# CC1314R10 register map
File version: 1.0
CPU: CM33 1.0, other endian, MPU, FPU, 3 interrupt priority bits
Registers are 32-bit, read-write, reset 0x0 unless marked. A register's access mark holds for its fields unless they carry their own. Offsets are from the block's base; [hi:lo] are bit positions; {n}, {i} and the like mark numbered series; 'fields as' and 'values as' point back to an identical list.

## CRYPTO (part 2 of 2) — DMA Crypto Core is a low power low gate count crypto core with DMA capability and local key storage.
Base 0x58024000
0x5DC AESBLKCNT1 — This counter keeps track of the number of data blocks during AES-CCM and AES-GCM operations. Reading and writing this counter allows interruption and resuming of long CCM or GCM operations. Note that internally, the block counter is used for AAD data as well as encryption/decryption data
  [24:0] AES_BLK_CNT_56_32 — [24:0] [56:32] of Internal block counter for AES GCM and CCM operations. These bits read the block count value that represents the number of blocks to go. This value is valid with saved_context_ready after a request for an intermediate GCM/CCM digest. Writing these registers will restore the internal block counter to the programmed value. This only needs to be done to prepare the engine to continue processing of an interrupted GCM or CCM operation. Also refer to the get_digest and gcm_ccm_continue bits in AES_CTRL register.
{0x600+4i} HASHDATAIN{i} (i=0..2) — HASH Data Input {i} The data input registers should be used to provide input data to the hash module through the slave interface.
  [31:0] HASH_DATA_IN wo — [31:0] HASH_DATA_IN[{32i+31}:{32i}] These registers must be written with the 512-bit or 1024-bit (depending on block size of chosen SHA-2 algorithm) input data. The data lines are connected directly to the data input of the hash module and hence into the engine's internal data buffer. Writing to each of the registers triggers a corresponding 32-bit write enable to the internal buffer. Note: The host may only write the input data buffer when HASHIOBUFCTRL.RFD_IN is 1. If the HASHIOBUFCTRL.RFD_IN is 0, the engine is busy with processing. During processing, it is not allowed to write new input data. For message lengths larger than a block size, multiple blocks of data are written to this input buffer using a handshake through flags of the HASHIOBUFCTRL register. All blocks except the last are required to be 512 bits (or 1024 bits depending on block size) in size. If the last block is not 512 bits ( or 1024 bits depending on block size) long, only the least significant bits of data must be written, but they must be padded with 0s to the next 32-bit boundary. Host read operations from these register addresses return 0s.
0x60C HASHDATAIN3 — HASH Data Input 3 The data input registers should be used to provide input data to the hash module through the slave interface.
  [31:0] HASH_DATA_IN wo — [31:0] HASH_DATA_IN[127:96] These registers must be written with the 512-bit or 1024-bit (depending on block size of chosen SHA-2 algorithm) input data. The data lines are connected directly to the data input of the hash module and hence into the engine's internal data buffer. Writing to each of the registers triggers a corresponding 32-bit write enable to the internal buffer. Note: The host may only write the input data buffer when the rfd_in bit of the HASH_IO_BUF_CTRL register is high. If the rfd_in bit is 0, the engine is busy with processing. During processing, it is not allowed to write new input data. For message lengths larger than a block size, multiple blocks of data are written to this input buffer using a handshake through flags of the HASH_IO_BUF_CTRL register. All blocks except the last are required to be 512 bits (or 1024 bits depending on block size) in size. If the last block is not 512 bits ( or 1024 bits depending on block size) long, only the least significant bits of data must be written, but they must be padded with 0s to the next 32-bit boundary. Host read operations from these register addresses return 0s.
0x610 HASHDATAIN4 — HASH Data Input 4 The data input registers should be used to provide input data to the hash module through the slave interface.
  [31:0] HASH_DATA_IN wo — [31:0] HASH_DATA_IN[159:128] These registers must be written with the 512-bit or 1024-bit (depending on block size of chosen SHA-2 algorithm) input data. The data lines are connected directly to the data input of the hash module and hence into the engine's internal data buffer. Writing to each of the registers triggers a corresponding 32-bit write enable to the internal buffer. Note: The host may only write the input data buffer when HASHIOBUFCTRL.RFD_IN is '1'. If the HASHIOBUFCTRL.RFD_IN is 0, the engine is busy with processing. During processing, it is not allowed to write new input data. For message lengths larger than a block size, multiple blocks of data are written to this input buffer using a handshake through flags of the HASHIOBUFCTRL register. All blocks except the last are required to be 512 bits (or 1024 bits depending on block size) in size. If the last block is not 512 bits ( or 1024 bits depending on block size) long, only the least significant bits of data must be written, but they must be padded with 0s to the next 32-bit boundary. Host read operations from these register addresses return 0s.
{0x600+4i} HASHDATAIN{i} (i=5..27) — HASH Data Input {i} The data input registers should be used to provide input data to the hash module through the slave interface.
  fields as HASHDATAIN0
0x670 HASHDATAIN28 — HASH Data Input 28 The data input registers should be used to provide input data to the hash module through the slave interface.
  [31:0] HASH_DATA_IN wo — [31:0] HASH_DATA_IN[923:896] These registers must be written with the 512-bit or 1024-bit (depending on block size of chosen SHA-2 algorithm) input data. The data lines are connected directly to the data input of the hash module and hence into the engine's internal data buffer. Writing to each of the registers triggers a corresponding 32-bit write enable to the internal buffer. Note: The host may only write the input data buffer when HASHIOBUFCTRL.RFD_IN is 1. If the HASHIOBUFCTRL.RFD_IN is 0, the engine is busy with processing. During processing, it is not allowed to write new input data. For message lengths larger than a block size, multiple blocks of data are written to this input buffer using a handshake through flags of the HASHIOBUFCTRL register. All blocks except the last are required to be 512 bits (or 1024 bits depending on block size) in size. If the last block is not 512 bits ( or 1024 bits depending on block size) long, only the least significant bits of data must be written, but they must be padded with 0s to the next 32-bit boundary. Host read operations from these register addresses return 0s.
0x674 HASHDATAIN29 — HASH Data Input 29 The data input registers should be used to provide input data to the hash module through the slave interface.
  [31:0] HASH_DATA_IN wo — [31:0] HASH_DATA_IN[959:924] These registers must be written with the 512-bit or 1024-bit (depending on block size of chosen SHA-2 algorithm) input data. The data lines are connected directly to the data input of the hash module and hence into the engine's internal data buffer. Writing to each of the registers triggers a corresponding 32-bit write enable to the internal buffer. Note: The host may only write the input data buffer when HASHIOBUFCTRL.RFD_IN is 1. If the HASHIOBUFCTRL.RFD_IN is 0, the engine is busy with processing. During processing, it is not allowed to write new input data. For message lengths larger than a block size, multiple blocks of data are written to this input buffer using a handshake through flags of the HASHIOBUFCTRL register. All blocks except the last are required to be 512 bits (or 1024 bits depending on block size) in size. If the last block is not 512 bits ( or 1024 bits depending on block size) long, only the least significant bits of data must be written, but they must be padded with 0s to the next 32-bit boundary. Host read operations from these register addresses return 0s.
0x678 HASHDATAIN30 — HASH Data Input 30 The data input registers should be used to provide input data to the hash module through the slave interface.
  [31:0] HASH_DATA_IN wo — [31:0] HASH_DATA_IN[991:960] These registers must be written with the 512-bit or 1024-bit (depending on block size of chosen SHA-2 algorithm) input data. The data lines are connected directly to the data input of the hash module and hence into the engine's internal data buffer. Writing to each of the registers triggers a corresponding 32-bit write enable to the internal buffer. Note: The host may only write the input data buffer when HASHIOBUFCTRL.RFD_IN is 1. If the HASHIOBUFCTRL.RFD_IN is 0, the engine is busy with processing. During processing, it is not allowed to write new input data. For message lengths larger than a block size, multiple blocks of data are written to this input buffer using a handshake through flags of the HASHIOBUFCTRL register. All blocks except the last are required to be 512 bits (or 1024 bits depending on block size) in size. If the last block is not 512 bits ( or 1024 bits depending on block size) long, only the least significant bits of data must be written, but they must be padded with 0s to the next 32-bit boundary. Host read operations from these register addresses return 0s.
0x67C HASHDATAIN31 — HASH Data Input 31 The data input registers should be used to provide input data to the hash module through the slave interface.
  [31:0] HASH_DATA_IN wo — [31:0] HASH_DATA_IN[1023:992] These registers must be written with the 512-bit or 1024-bit (depending on block size of chosen SHA-2 algorithm) input data. The data lines are connected directly to the data input of the hash module and hence into the engine's internal data buffer. Writing to each of the registers triggers a corresponding 32-bit write enable to the internal buffer. Note: The host may only write the input data buffer when HASHIOBUFCTRL.RFD_IN is 1. If the HASHIOBUFCTRL.RFD_IN is 0, the engine is busy with processing. During processing, it is not allowed to write new input data. For message lengths larger than a block size, multiple blocks of data are written to this input buffer using a handshake through flags of the HASHIOBUFCTRL register. All blocks except the last are required to be 512 bits (or 1024 bits depending on block size) in size. If the last block is not 512 bits ( or 1024 bits depending on block size) long, only the least significant bits of data must be written, but they must be padded with 0s to the next 32-bit boundary. Host read operations from these register addresses return 0s.
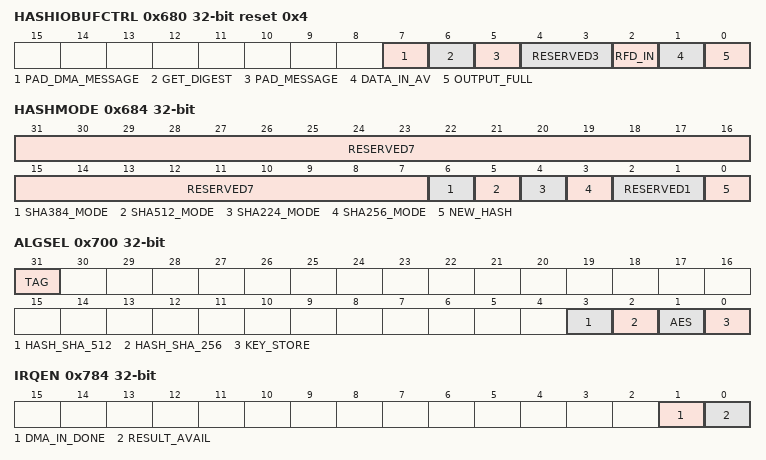
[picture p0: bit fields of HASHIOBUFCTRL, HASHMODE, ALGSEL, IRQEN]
0x680 HASHIOBUFCTRL reset 0x4 — HASH Input_Output Buffer Control This register pair shares a single address location and contains bits that control and monitor the data flow between the host and the hash engine.
  [7] PAD_DMA_MESSAGE — [7:7] Note: This bit must only be used when data is supplied through the DMA. It should not be used when data is supplied through the slave interface. This bit indicates whether the hash engine has to pad the message, received through the DMA and finalize the hash. When set to 1, the hash engine pads the last block using the programmed length. After padding, the final hash result is calculated. When set to 0, the hash engine treats the last written block as block-size aligned and calculates the intermediate digest. This bit is automatically cleared when the last DMA data block is arrived in the hash engine.
  [6] GET_DIGEST — [6:6] Note: The bit description below is only applicable when data is sent through the slave interface. This bit must be set to 0 when data is received through the DMA. This bit indicates whether the hash engine should provide the hash digest. When provided simultaneously with data_in_av, the hash digest is provided after processing the data that is currently in the HASHDATAINn register. When provided without data_in_av, the current internal digest buffer value is copied to the HASHDIGESTn registers. The host must write a 1 to this bit to make the intermediate hash digest available. Writing 0 to this bit has no effect. This bit is automatically cleared (that is, reads 0) when the hash engine has processed the contents of the HASHDATAINn register. In the period between this bit is set by the host and the actual HASHDATAINn processing, this bit reads 1.
  [5] PAD_MESSAGE — [5:5] Note: The bit description below is only applicable when data is sent through the slave interface. This bit must be set to 0 when data is received through the DMA. This bit indicates that the HASHDATAINn registers hold the last data of the message and hash padding must be applied. The host must write this bit to 1 in order to indicate to the hash engine that the HASHDATAINn register currently holds the last data of the message. When pad_message is set to 1, the hash engine will add padding bits to the data currently in the HASHDATAINn register. When the last message block is smaller than 1024 bits for SHA-512/384 or 512 bits for SHA-256/224, the pad_message bit must be set to ‘1’ together with the data_in_av bit. When the last message block is equal to the block size, pad_message may be set together with data_in_av. In this case, the pad_message bit may also be set after the last data block has been written to the hash engine (so when the rfd_in bit has become ‘1’ again after writing the last data block). Writing 0 to this bit has no effect. This bit is automatically cleared (i.e. reads 0) by the hash engine. This bit reads 1 between the time it was set by the host and the hash engine interpreted its value.
  [4:3] RESERVED3 — [4:3] Write 0s and ignore on reading
  [2] RFD_IN — [2:2] Note: The bit description below is only applicable when data is sent through the slave interface. This bit can be ignored when data is received through the DMA. Read-only status of the input buffer of the hash engine. When 1, the input buffer of the hash engine can accept new data; the HASHDATAINn registers can safely be populated with new data. When 0, the input buffer of the hash engine is processing the data that is currently in HASHDATAINn; writing new data to these registers is not allowed.
  [1] DATA_IN_AV — [1:1] Note: The bit description below is only applicable when data is sent through the slave interface. This bit must be set to 0 when data is received through the DMA. This bit indicates that the HASHDATAINn registers contain new input data for processing. The host must write a 1 to this bit to start processing the data in HASHDATAINn; the hash engine will process the new data as soon as it is ready for it (rfd_in bit is 1). Writing 0 to this bit has no effect. This bit is automatically cleared (i.e. reads as 0) when the hash engine starts processing the HASHDATAINn contents. This bit reads 1 between the time it was set by the host and the hash engine actually starts processing the input data block.
  [0] OUTPUT_FULL — [0:0] Indicates that the output buffer registers (HASHDIGESTn) are available for reading by the host. When this bit reads 0, the output buffer registers are released; the hash engine is allowed to write new data to it. In this case, the registers should not be read by the host. When this bit reads 1, the hash engine has stored the result of the latest hash operation in the output buffer registers. As long as this bit reads 1, the host may read output buffer registers and the hash engine is prevented from writing new data to the output buffer. After retrieving the hash result data from the output buffer, the host must write a 1 to this bit to clear it. This makes the digest output buffer available for the hash engine to store new hash results. Writing 0 to this bit has no effect. Note: If this bit is asserted (1) no new operation should be started before the digest is retrieved from the hash engine and this bit is cleared (0).
0x684 HASHMODE
  [31:7] RESERVED7 wo — [31:7] Write 0s and ignore on reading
  [6] SHA384_MODE wo — [6:6] The host must write this bit with 1 prior to processing a SHA 384 session.
  [5] SHA512_MODE wo — [5:5] The host must write this bit with 1 prior to processing a SHA 512 session.
  [4] SHA224_MODE wo — [4:4] The host must write this bit with 1 prior to processing a SHA 224 session.
  [3] SHA256_MODE wo — [3:3] The host must write this bit with 1 prior to processing a SHA 256 session.
  [2:1] RESERVED1 wo — [2:1] Write 0s and ignore on reading
  [0] NEW_HASH wo — [0:0] When set to 1, it indicates that the hash engine must start processing a new hash session. The [HASHDIGESTn.* ] registers will automatically be loaded with the initial hash algorithm constants of the selected hash algorithm. When this bit is 0 while the hash processing is started, the initial hash algorithm constants are not loaded in the HASHDIGESTn registers. The hash engine will start processing with the digest that is currently in its internal HASHDIGESTn registers. This bit is automatically cleared when hash processing is started.
0x688 HASHINLENL — HASH Input Length LSB
  [31:0] LENGTH_IN wo — [31:0] LENGTH_IN[31:0] Message length registers. The content of these registers is used by the hash engine during the message padding phase of the hash session. The data lines of this registers are directly connected to the interface of the hash engine. For a write operation by the host, these registers should be written with the message length in bits. Final hash operations: The total input data length must be programmed for new hash operations that require finalization (padding). The input data must be provided through the slave or DMA interface. Continued hash operations (finalized): For continued hash operations that require finalization, the total message length must be programmed, including the length of previously hashed data that corresponds to the written input digest. Non-final hash operations: For hash operations that do not require finalization (input data length is multiple of 1024-bits for SHA-512, which is SHA-512 data block size. Or multiple of 512-bits for SHA-256, which is SHA-256 data block size), the length field does not need to be programmed since it is not used by the operation If the message length in bits is below (2^32-1), then only this register needs to be written. The hardware automatically sets HASH_LENGTH_IN_H to 0s in this case. The host may write the length register at any time during the hash session when the HASHIOBUFCTRL.RFD_IN is high. The length register must be written before the last data of the active hash session is written into the hash engine. host read operations from these register locations will return 0s. Note: When getting data from DMA, this register must be programmed before DMA is programmed to start.
0x68C HASHINLENH — HASH Input Length MSB
  [31:0] LENGTH_IN wo — [31:0] LENGTH_IN[63:32] Message length registers. The content of these registers is used by the hash engine during the message padding phase of the hash session. The data lines of this registers are directly connected to the interface of the hash engine. For a write operation by the host, these registers should be written with the message length in bits. Final hash operations: The total input data length must be programmed for new hash operations that require finalization (padding). The input data must be provided through the slave or DMA interface. Continued hash operations (finalized): For continued hash operations that require finalization, the total message length must be programmed, including the length of previously hashed data that corresponds to the written input digest. Non-final hash operations: For hash operations that do not require finalization (input data length is multiple of 1024-bits for SHA-512, which is SHA-512 data block size. Or multiple of 512-bits for SHA-256, which is SHA-256 data block size), the length field does not need to be programmed since it is not used by the operation. If the message length in bits is below (2^32-1), then only HASHINLENL needs to be written. The hardware automatically sets HASH_LENGTH_IN_H to 0s in this case. The host may write the length register at any time during the hash session when the HASHIOBUFCTRL.RFD_IN is high. The length register must be written before the last data of the active hash session is written into the hash engine. host read operations from these register locations will return 0s. Note: When getting data from DMA, this register must be programmed before DMA is programmed to start.
0x6C0 HASHDIGESTA — HASH Digest A The hash digest registers consist of sixteen 32-bit registers, named HASHDIGESTA to HASHDIGESTP. After processing a message, the output digest can be read from these registers. These registers can be written with an intermediate hash result for continued hash operations.
  [31:0] HASH_DIGEST — [31:0] HASH_DIGEST[31:0] Hash digest registers Write operation: Continued hash: These registers should be written with the context data, before the start of a resumed hash session (the HASHMODE.NEW_HASH bit is 0 when starting a hash session). New hash: When initiating a new hash session (theHASHMODE.NEW_HASH bit is 1), the internal digest registers are automatically set to the SHA-256 algorithm constant and these register should not be written. Reading from these registers provides the intermediate hash result (non-final hash operation) or the final hash result (final hash operation) after data processing.
0x6C4 HASHDIGESTB — HASH Digest B The hash digest registers consist of sixteen 32-bit registers, named HASHDIGESTA to HASHDIGESTP. After processing a message, the output digest can be read from these registers. These registers can be written with an intermediate hash result for continued hash operations.
  [31:0] HASH_DIGEST — [31:0] HASH_DIGEST[63:32] Hash digest registers Write operation: Continued hash: These registers should be written with the context data, before the start of a resumed hash session (the HASHMODE.NEW_HASH bit is 0 when starting a hash session). New hash: When initiating a new hash session (theHASHMODE.NEW_HASH bit is 1), the internal digest registers are automatically set to the SHA-256 algorithm constant and these register should not be written. Reading from these registers provides the intermediate hash result (non-final hash operation) or the final hash result (final hash operation) after data processing.
0x6C8 HASHDIGESTC — HASH Digest C The hash digest registers consist of sixteen 32-bit registers, named HASHDIGESTA to HASHDIGESTP. After processing a message, the output digest can be read from these registers. These registers can be written with an intermediate hash result for continued hash operations.
  [31:0] HASH_DIGEST — [31:0] HASH_DIGEST[95:64] Hash digest registers Write operation: Continued hash: These registers should be written with the context data, before the start of a resumed hash session (the HASHMODE.NEW_HASH bit is 0 when starting a hash session). New hash: When initiating a new hash session (theHASHMODE.NEW_HASH bit is 1), the internal digest registers are automatically set to the SHA-256 algorithm constant and these register should not be written. Reading from these registers provides the intermediate hash result (non-final hash operation) or the final hash result (final hash operation) after data processing.
0x6CC HASHDIGESTD — HASH Digest D The hash digest registers consist of sixteen 32-bit registers, named HASHDIGESTA to HASHDIGESTP. After processing a message, the output digest can be read from these registers. These registers can be written with an intermediate hash result for continued hash operations.
  [31:0] HASH_DIGEST — [31:0] HASH_DIGEST[127:96] Hash digest registers Write operation: Continued hash: These registers should be written with the context data, before the start of a resumed hash session (the HASHMODE.NEW_HASH bit is 0 when starting a hash session). New hash: When initiating a new hash session (theHASHMODE.NEW_HASH bit is 1), the internal digest registers are automatically set to the SHA-256 algorithm constant and these register should not be written. Reading from these registers provides the intermediate hash result (non-final hash operation) or the final hash result (final hash operation) after data processing.
0x6D0 HASHDIGESTE — HASH Digest E The hash digest registers consist of sixteen 32-bit registers, named HASHDIGESTA to HASHDIGESTP. After processing a message, the output digest can be read from these registers. These registers can be written with an intermediate hash result for continued hash operations.
  [31:0] HASH_DIGEST — [31:0] HASH_DIGEST[159:128] Hash digest registers Write operation: Continued hash: These registers should be written with the context data, before the start of a resumed hash session (the HASHMODE.NEW_HASH bit is 0 when starting a hash session). New hash: When initiating a new hash session (theHASHMODE.NEW_HASH bit is 1), the internal digest registers are automatically set to the SHA-256 algorithm constant and these register should not be written. Reading from these registers provides the intermediate hash result (non-final hash operation) or the final hash result (final hash operation) after data processing.
0x6D4 HASHDIGESTF — HASH Digest F The hash digest registers consist of sixteen 32-bit registers, named HASHDIGESTA to HASHDIGESTP. After processing a message, the output digest can be read from these registers. These registers can be written with an intermediate hash result for continued hash operations.
  [31:0] HASH_DIGEST — [31:0] HASH_DIGEST[191:160] Hash digest registers Write operation: Continued hash: These registers should be written with the context data, before the start of a resumed hash session (the HASHMODE.NEW_HASH bit is 0 when starting a hash session). New hash: When initiating a new hash session (theHASHMODE.NEW_HASH bit is 1), the internal digest registers are automatically set to the SHA-256 algorithm constant and these register should not be written. Reading from these registers provides the intermediate hash result (non-final hash operation) or the final hash result (final hash operation) after data processing.
0x6D8 HASHDIGESTG — HASH Digest G The hash digest registers consist of sixteen 32-bit registers, named HASHDIGESTA to HASHDIGESTP. After processing a message, the output digest can be read from these registers. These registers can be written with an intermediate hash result for continued hash operations.
  [31:0] HASH_DIGEST — [31:0] HASH_DIGEST[223:192] Hash digest registers Write operation: Continued hash: These registers should be written with the context data, before the start of a resumed hash session (the HASHMODE.NEW_HASH bit is 0 when starting a hash session). New hash: When initiating a new hash session (theHASHMODE.NEW_HASH bit is 1), the internal digest registers are automatically set to the SHA-256 algorithm constant and these register should not be written. Reading from these registers provides the intermediate hash result (non-final hash operation) or the final hash result (final hash operation) after data processing.
0x6DC HASHDIGESTH — HASH Digest H The hash digest registers consist of sixteen 32-bit registers, named HASHDIGESTA to HASHDIGESTP. After processing a message, the output digest can be read from these registers. These registers can be written with an intermediate hash result for continued hash operations.
  [31:0] HASH_DIGEST — [31:0] HASH_DIGEST[255:224] Hash digest registers Write operation: Continued hash: These registers should be written with the context data, before the start of a resumed hash session (the HASHMODE.NEW_HASH bit is 0 when starting a hash session). New hash: When initiating a new hash session (theHASHMODE.NEW_HASH bit is 1), the internal digest registers are automatically set to the SHA-256 algorithm constant and these register should not be written. Reading from these registers provides the intermediate hash result (non-final hash operation) or the final hash result (final hash operation) after data processing.
0x6E0 HASHDIGESTI — HASH Digest I The hash digest registers consist of sixteen 32-bit registers, named HASHDIGESTA to HASHDIGESTP. After processing a message, the output digest can be read from these registers. These registers can be written with an intermediate hash result for continued hash operations.
  [31:0] HASH_DIGEST — [31:0] HASH_DIGEST[287:256] Hash digest registers Write operation: Continued hash: These registers should be written with the context data, before the start of a resumed hash session (the HASHMODE.NEW_HASH bit is 0 when starting a hash session). New hash: When initiating a new hash session (theHASHMODE.NEW_HASH bit is 1), the internal digest registers are automatically set to the SHA-256 algorithm constant and these register should not be written. Reading from these registers provides the intermediate hash result (non-final hash operation) or the final hash result (final hash operation) after data processing.
0x6E4 HASHDIGESTJ — HASH Digest J The hash digest registers consist of sixteen 32-bit registers, named HASHDIGESTA to HASHDIGESTP. After processing a message, the output digest can be read from these registers. These registers can be written with an intermediate hash result for continued hash operations.
  [31:0] HASH_DIGEST — [31:0] HASH_DIGEST[319:288] Hash digest registers Write operation: Continued hash: These registers should be written with the context data, before the start of a resumed hash session (the HASHMODE.NEW_HASH bit is 0 when starting a hash session). New hash: When initiating a new hash session (theHASHMODE.NEW_HASH bit is 1), the internal digest registers are automatically set to the SHA-256 algorithm constant and these register should not be written. Reading from these registers provides the intermediate hash result (non-final hash operation) or the final hash result (final hash operation) after data processing.
0x6E8 HASHDIGESTK — HASH Digest K The hash digest registers consist of sixteen 32-bit registers, named HASHDIGESTA to HASHDIGESTP. After processing a message, the output digest can be read from these registers. These registers can be written with an intermediate hash result for continued hash operations.
  [31:0] HASH_DIGEST — [31:0] HASH_DIGEST[351:320] Hash digest registers Write operation: Continued hash: These registers should be written with the context data, before the start of a resumed hash session (the HASHMODE.NEW_HASH bit is 0 when starting a hash session). New hash: When initiating a new hash session (theHASHMODE.NEW_HASH bit is 1), the internal digest registers are automatically set to the SHA-256 algorithm constant and these register should not be written. Reading from these registers provides the intermediate hash result (non-final hash operation) or the final hash result (final hash operation) after data processing.
0x6EC HASHDIGESTL — HASH Digest L The hash digest registers consist of sixteen 32-bit registers, named HASHDIGESTA to HASHDIGESTP. After processing a message, the output digest can be read from these registers. These registers can be written with an intermediate hash result for continued hash operations.
  [31:0] HASH_DIGEST — [31:0] HASH_DIGEST[383:352] Hash digest registers Write operation: Continued hash: These registers should be written with the context data, before the start of a resumed hash session (the HASHMODE.NEW_HASH bit is 0 when starting a hash session). New hash: When initiating a new hash session (theHASHMODE.NEW_HASH bit is 1), the internal digest registers are automatically set to the SHA-256 algorithm constant and these register should not be written. Reading from these registers provides the intermediate hash result (non-final hash operation) or the final hash result (final hash operation) after data processing.
0x6F0 HASHDIGESTM — HASH Digest M The hash digest registers consist of sixteen 32-bit registers, named HASHDIGESTA to HASHDIGESTP. After processing a message, the output digest can be read from these registers. These registers can be written with an intermediate hash result for continued hash operations.
  [31:0] HASH_DIGEST — [31:0] HASH_DIGEST[415:384] Hash digest registers Write operation: Continued hash: These registers should be written with the context data, before the start of a resumed hash session (the HASHMODE.NEW_HASH bit is 0 when starting a hash session). New hash: When initiating a new hash session (theHASHMODE.NEW_HASH bit is 1), the internal digest registers are automatically set to the SHA-256 algorithm constant and these register should not be written. Reading from these registers provides the intermediate hash result (non-final hash operation) or the final hash result (final hash operation) after data processing.
0x6F4 HASHDIGESTN — HASH Digest N The hash digest registers consist of sixteen 32-bit registers, named HASHDIGESTA to HASHDIGESTP. After processing a message, the output digest can be read from these registers. These registers can be written with an intermediate hash result for continued hash operations.
  [31:0] HASH_DIGEST — [31:0] HASH_DIGEST[447:416] Hash digest registers Write operation: Continued hash: These registers should be written with the context data, before the start of a resumed hash session (the HASHMODE.NEW_HASH bit is 0 when starting a hash session). New hash: When initiating a new hash session (theHASHMODE.NEW_HASH bit is 1), the internal digest registers are automatically set to the SHA-256 algorithm constant and these register should not be written. Reading from these registers provides the intermediate hash result (non-final hash operation) or the final hash result (final hash operation) after data processing.
0x6F8 HASHDIGESTO — HASH Digest 0 The hash digest registers consist of sixteen 32-bit registers, named HASHDIGESTA to HASHDIGESTP. After processing a message, the output digest can be read from these registers. These registers can be written with an intermediate hash result for continued hash operations.
  [31:0] HASH_DIGEST — [31:0] HASH_DIGEST[479:448] Hash digest registers Write operation: Continued hash: These registers should be written with the context data, before the start of a resumed hash session (the HASHMODE.NEW_HASH bit is 0 when starting a hash session). New hash: When initiating a new hash session (theHASHMODE.NEW_HASH bit is 1), the internal digest registers are automatically set to the SHA-256 algorithm constant and these register should not be written. Reading from these registers provides the intermediate hash result (non-final hash operation) or the final hash result (final hash operation) after data processing.
0x6FC HASHDIGESTP — HASH Digest P The hash digest registers consist of sixteen 32-bit registers, named HASHDIGESTA to HASHDIGESTP. After processing a message, the output digest can be read from these registers. These registers can be written with an intermediate hash result for continued hash operations.
  [31:0] HASH_DIGEST — [31:0] HASH_DIGEST[511:480] Hash digest registers Write operation: Continued hash: These registers should be written with the context data, before the start of a resumed hash session (the HASHMODE.NEW_HASH bit is 0 when starting a hash session). New hash: When initiating a new hash session (theHASHMODE.NEW_HASH bit is 1), the internal digest registers are automatically set to the SHA-256 algorithm constant and these register should not be written. Reading from these registers provides the intermediate hash result (non-final hash operation) or the final hash result (final hash operation) after data processing.
0x700 ALGSEL — Algorithm Select This algorithm selection register configures the internal destination of the DMA controller.
  [31] TAG — [31:31] If this bit is cleared to 0, the DMA operation involves only data. If this bit is set, the DMA operation includes a TAG (Authentication Result / Digest). For SHA-2 operation, a DMA must be set up for both input data and TAG. For any other selected module, setting this bit only allows a DMA that reads the TAG. No data allowed to be transferred to or from the selected module via the DMA.
  [3] HASH_SHA_512 — [3:3] If set to one, selects the Hash engine as destination for the DMA. The maximum transfer size to DMA engine is set to 128 bytes for reading and 64 bytes for writing (the latter is only applicable if the hash result is written out via DMA).
  [2] HASH_SHA_256 — [2:2] If set to one, selects the hash engine in 256B mode as destination for the DMA The maximum transfer size to DMA engine is set to 64 bytes for reading and 32 bytes for writing (the latter is only applicable if the hash result is written out through the DMA).
  [1] AES — [1:1] If set to one, selects the AES engine as source/destination for the DMA The read and write maximum transfer size to the DMA engine is set to 16 bytes.
  [0] KEY_STORE — [0:0] If set to one, selects the Key Store as destination for the DMA The maximum transfer size to DMA engine is set to 32 bytes (however transfers of 16, 24 and 32 bytes are allowed)
0x704 DMAPROTCTL — DMA Protection Control Master PROT privileged access enable This register enables the second bit (bit [1]) of the AHB HPROT bus of the AHB master interface when a read action of key(s) is performed on the AHB master interface for writing keys into the store module.
  [0] PROT_EN — [0:0] Select AHB transfer protection control for DMA transfers using the key store area as destination. 0 : transfers use 'USER' type access. 1 : transfers use 'PRIVILEGED' type access.
0x740 SWRESET — Software Reset
  [0] SW_RESET — [0:0] If this bit is set to 1, the following modules are reset: - Master control internal state is reset. That includes interrupt, error status register, and result available interrupt generation FSM. - Key store module state is reset. That includes clearing the written area flags; therefore, the keys must be reloaded to the key store module. Writing 0 has no effect. The bit is self cleared after executing the reset.
0x780 IRQTYPE — Control Interrupt Configuration
  [0] LEVEL — [0:0] If this bit is 0, the interrupt output is a pulse. If this bit is set to 1, the interrupt is a level interrupt that must be cleared by writing the interrupt clear register. This bit is applicable for both interrupt output signals.
0x784 IRQEN — Control Interrupt Enable
  [1] DMA_IN_DONE — [1:1] If this bit is set to 0, the DMA input done interrupt disabled If this bit is set to 1, the DMA input done interrupt enabled.
  [0] RESULT_AVAIL — [0:0] If this bit is set to 0, the Result Available interrupt is disabled If this bit is set to 1, the Result Available interrupt is enabled.
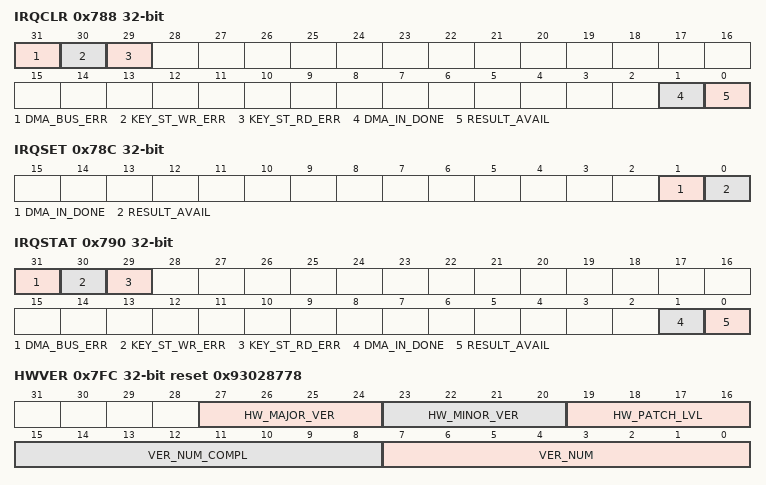
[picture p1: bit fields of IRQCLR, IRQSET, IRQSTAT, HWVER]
0x788 IRQCLR — Control Interrupt Clear
  [31] DMA_BUS_ERR wo — [31:31] If 1 is written to this bit, the DMA bus error status is cleared. Writing 0 has no effect.
  [30] KEY_ST_WR_ERR wo — [30:30] If 1 is written to this bit, the key store write error status is cleared. Writing 0 has no effect.
  [29] KEY_ST_RD_ERR wo — [29:29] If 1 is written to this bit, the key store read error status is cleared. Writing 0 has no effect.
  [1] DMA_IN_DONE wo — [1:1] If 1 is written to this bit, the DMA in done interrupt status is cleared. Writing 0 has no effect. Note that clearing an interrupt makes sense only if the interrupt output is programmed as level (refer to IRQTYPE).
  [0] RESULT_AVAIL wo — [0:0] If 1 is written to this bit, the result available interrupt status is cleared. Writing 0 has no effect. Note that clearing an interrupt makes sense only if the interrupt output is programmed as level (refer to IRQTYPE).
0x78C IRQSET — Control Interrupt Set
  [1] DMA_IN_DONE wo — [1:1] If 1 is written to this bit, the DMA data in done interrupt is set. Writing 0 has no effect. If the interrupt configuration register is programmed to pulse, clearing the DMA data in done interrupt is not needed. If it is programmed to level, clearing the interrupt output should be done by writing the interrupt clear register (IRQCLR.DMA_IN_DONE).
  [0] RESULT_AVAIL wo — [0:0] If 1 is written to this bit, the result available interrupt is set Writing 0 has no effect. If the interrupt configuration register is programmed to pulse, clearing the result available interrupt is not needed. If it is programmed to level, clearing the interrupt should be done by writing the interrupt clear register (IRQCLR.RESULT_AVAIL).
0x790 IRQSTAT — Control Interrupt Status
  [31] DMA_BUS_ERR ro — [31:31] This bit is set when a DMA bus error is detected during a DMA operation. The value of this register is held until it is cleared through the IRQCLR.DMA_BUS_ERR Note: This error is asserted if an error is detected on the AHB master interface during a DMA operation.
  [30] KEY_ST_WR_ERR ro — [30:30] This bit is set when a write error is detected during the DMA write operation to the key store memory. The value of this register is held until it is cleared through the IRQCLR.KEY_ST_WR_ERR register. Note: This error is asserted if a DMA operation does not cover a full key area or more areas are written than expected.
  [29] KEY_ST_RD_ERR ro — [29:29] This bit is set when a read error is detected during the read of a key from the key store, while copying it to the AES core. The value of this register is held until it is cleared through the IRQCLR.KEY_ST_RD_ERR register. Note: This error is asserted if a key location is selected in the key store that is not available.
  [1] DMA_IN_DONE ro — [1:1] This read only bit returns the actual DMA data in done interrupt status
  [0] RESULT_AVAIL ro — [0:0] This read only bit returns the actual result available interrupt status
0x7FC HWVER reset 0x93028778 — Hardware Version
  [27:24] HW_MAJOR_VER ro — [27:24] Major version number
  [23:20] HW_MINOR_VER ro — [23:20] Minor version number
  [19:16] HW_PATCH_LVL ro — [19:16] Patch level Starts at 0 at first delivery of this version
  [15:8] VER_NUM_COMPL ro — [15:8] These bits simply contain the complement of bits [7:0] (0x87), used by a driver to ascertain that the EIP-120t register is indeed read.
  [7:0] VER_NUM ro — [7:0] These bits encode the EIP number for the EIP-120t, this field contains the value 120 (decimal) or 0x78.
